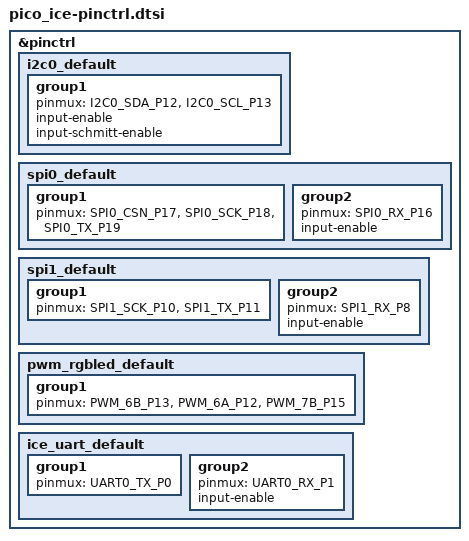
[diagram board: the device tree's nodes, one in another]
/*
 * Copyright (c) 2025 tinyVision.ai
 * SPDX-License-Identifier: Apache-2.0
 */

#include <zephyr/dt-bindings/pinctrl/rpi-pico-rp2040-pinctrl.h>
&pinctrl {
	i2c0_default: i2c0_default {
		group1 {
			pinmux = <I2C0_SDA_P12>, <I2C0_SCL_P13>;
			input-enable;
			input-schmitt-enable;
		};
	};

	spi0_default: spi0_default {
		group1 {
			pinmux = <SPI0_CSN_P17>, <SPI0_SCK_P18>, <SPI0_TX_P19>;
		};
		group2 {
			pinmux = <SPI0_RX_P16>;
			input-enable;
		};
	};

	spi1_default: spi1_default {
		group1 {
			pinmux = <SPI1_SCK_P10>, <SPI1_TX_P11>;
		};
		group2 {
			pinmux = <SPI1_RX_P8>;
			input-enable;
		};
	};

	pwm_rgbled_default: pwm_rgbled_default {
		group1 {
			pinmux = <PWM_6B_P13>, <PWM_6A_P12>, <PWM_7B_P15>;
		};
	};

	ice_uart_default: ice_uart_default {
		group1 {
			pinmux = <UART0_TX_P0>;
		};
		group2 {
			pinmux = <UART0_RX_P1>;
			input-enable;
		};
	};
};
